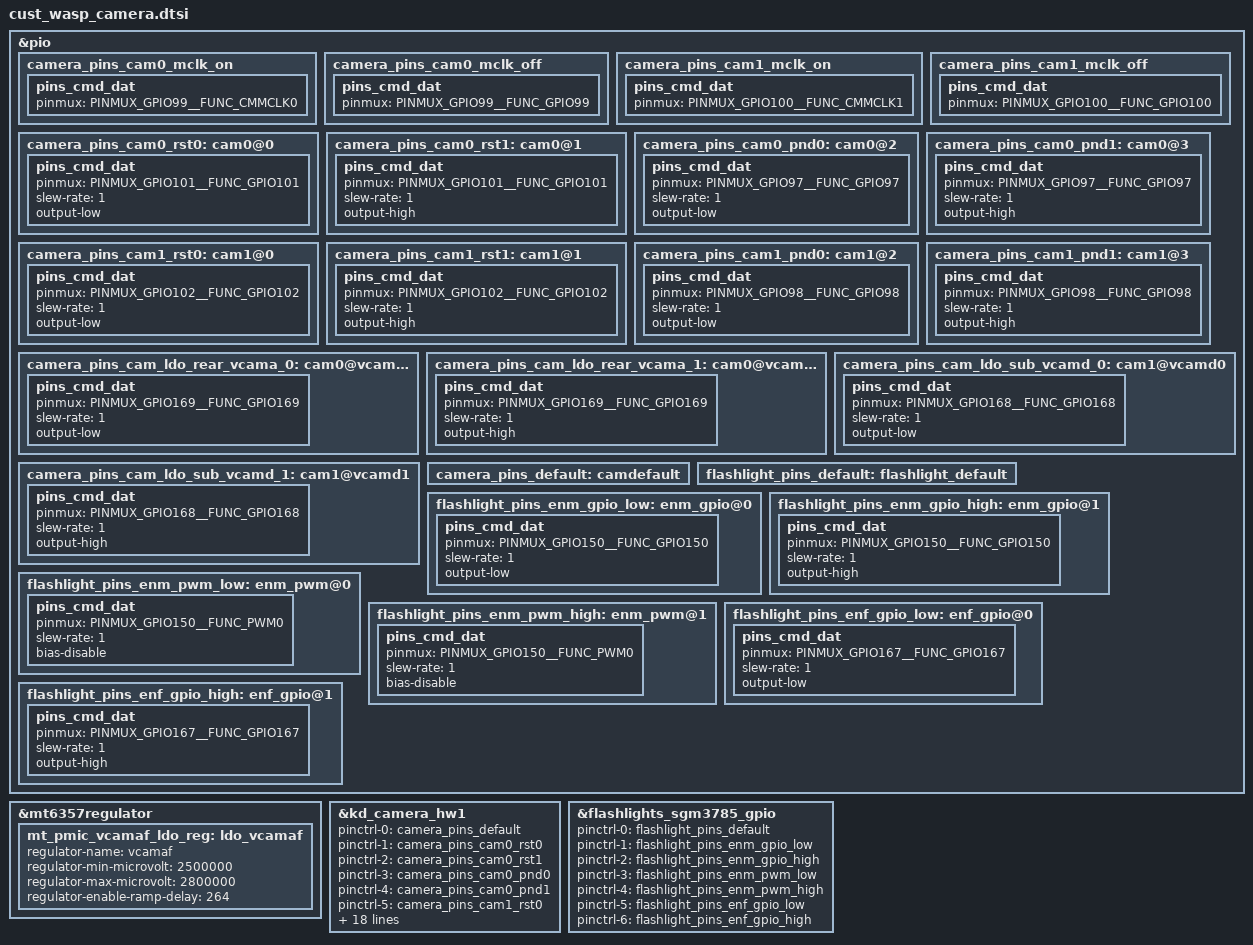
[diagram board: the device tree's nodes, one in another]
// SPDX-License-Identifier: GPL-2.0+
/*
 * Copyright (c) 2019 MediaTek Inc.
 *
 */

/* CAMERA GPIO standardization */
&pio {
	camera_pins_cam0_mclk_on: camera_pins_cam0_mclk_on {
		pins_cmd_dat {
			pinmux = <PINMUX_GPIO99__FUNC_CMMCLK0>;
		};
	};
	camera_pins_cam0_mclk_off: camera_pins_cam0_mclk_off {
		pins_cmd_dat {
			pinmux = <PINMUX_GPIO99__FUNC_GPIO99>;
		};
	};
	camera_pins_cam1_mclk_on: camera_pins_cam1_mclk_on {
		pins_cmd_dat {
			pinmux = <PINMUX_GPIO100__FUNC_CMMCLK1>;
		};
	};
	camera_pins_cam1_mclk_off: camera_pins_cam1_mclk_off {
		pins_cmd_dat {
			pinmux = <PINMUX_GPIO100__FUNC_GPIO100>;
		};
	};
	camera_pins_cam0_rst0: cam0@0 {
		pins_cmd_dat {
			pinmux = <PINMUX_GPIO101__FUNC_GPIO101>;
			slew-rate = <1>;
			output-low;
		};
	};
	camera_pins_cam0_rst1: cam0@1 {
		pins_cmd_dat {
			pinmux = <PINMUX_GPIO101__FUNC_GPIO101>;
			slew-rate = <1>;
			output-high;
		};
	};
	camera_pins_cam0_pnd0: cam0@2 {
		pins_cmd_dat {
			pinmux = <PINMUX_GPIO97__FUNC_GPIO97>;
			slew-rate = <1>;
			output-low;
		};
	};
	camera_pins_cam0_pnd1: cam0@3 {
		pins_cmd_dat {
			pinmux = <PINMUX_GPIO97__FUNC_GPIO97>;
			slew-rate = <1>;
			output-high;
		};
	};
	camera_pins_cam1_rst0: cam1@0 {
		pins_cmd_dat {
			pinmux = <PINMUX_GPIO102__FUNC_GPIO102>;
			slew-rate = <1>;
			output-low;
		};
	};
	camera_pins_cam1_rst1: cam1@1 {
		pins_cmd_dat {
			pinmux = <PINMUX_GPIO102__FUNC_GPIO102>;
			slew-rate = <1>;
			output-high;
		};
	};
	camera_pins_cam1_pnd0: cam1@2 {
		pins_cmd_dat {
			pinmux = <PINMUX_GPIO98__FUNC_GPIO98>;
			slew-rate = <1>;
			output-low;
		};
	};
	camera_pins_cam1_pnd1: cam1@3 {
		pins_cmd_dat {
			pinmux = <PINMUX_GPIO98__FUNC_GPIO98>;
			slew-rate = <1>;
			output-high;
		};
	};
	camera_pins_cam_ldo_rear_vcama_0: cam0@vcama0 {
		pins_cmd_dat {
			pinmux = <PINMUX_GPIO169__FUNC_GPIO169>;
			slew-rate = <1>;
			output-low;
		};
	};
	camera_pins_cam_ldo_rear_vcama_1: cam0@vcama1 {
		pins_cmd_dat {
			pinmux = <PINMUX_GPIO169__FUNC_GPIO169>;
			slew-rate = <1>;
			output-high;
		};
	};
	camera_pins_cam_ldo_sub_vcamd_0: cam1@vcamd0 {
		pins_cmd_dat {
			pinmux = <PINMUX_GPIO168__FUNC_GPIO168>;
			slew-rate = <1>;
			output-low;
		};
	};
	camera_pins_cam_ldo_sub_vcamd_1: cam1@vcamd1 {
		pins_cmd_dat {
			pinmux = <PINMUX_GPIO168__FUNC_GPIO168>;
			slew-rate = <1>;
			output-high;
		};
	};
	camera_pins_default: camdefault {
	};
};

&mt6357regulator {
	mt_pmic_vcamaf_ldo_reg: ldo_vcamaf {
		regulator-name = "vcamaf";
		regulator-min-microvolt = <2500000>;
		regulator-max-microvolt = <2800000>;
		regulator-enable-ramp-delay = <264>;
	};
};

&kd_camera_hw1 {
	pinctrl-names = "default",
			"cam0_rst0",
			"cam0_rst1",
			"cam0_pnd0",
			"cam0_pnd1",
			"cam1_rst0",
			"cam1_rst1",
			"cam1_pnd0",
			"cam1_pnd1",
			"cam0_vcama_on",
			"cam0_vcama_off",
			"cam1_vcamd_on",
			"cam1_vcamd_off",
			"cam0_mclk_on",
			"cam0_mclk_off",
			"cam1_mclk_on",
			"cam1_mclk_off";

	pinctrl-0 = <&camera_pins_default>;
	pinctrl-1 = <&camera_pins_cam0_rst0>;
	pinctrl-2 = <&camera_pins_cam0_rst1>;
	pinctrl-3 = <&camera_pins_cam0_pnd0>;
	pinctrl-4 = <&camera_pins_cam0_pnd1>;
	pinctrl-5 = <&camera_pins_cam1_rst0>;
	pinctrl-6 = <&camera_pins_cam1_rst1>;
	pinctrl-7 = <&camera_pins_cam1_pnd0>;
	pinctrl-8 = <&camera_pins_cam1_pnd1>;
	pinctrl-9 = <&camera_pins_cam_ldo_rear_vcama_1>;
	pinctrl-10 = <&camera_pins_cam_ldo_rear_vcama_0>;
	pinctrl-11 = <&camera_pins_cam_ldo_sub_vcamd_1>;
	pinctrl-12 = <&camera_pins_cam_ldo_sub_vcamd_0>;
	pinctrl-13 = <&camera_pins_cam0_mclk_on>;
	pinctrl-14 = <&camera_pins_cam0_mclk_off>;
	pinctrl-15 = <&camera_pins_cam1_mclk_on>;
	pinctrl-16 = <&camera_pins_cam1_mclk_off>;

	cam0_vcama-supply = <&mt_pmic_vcama_ldo_reg>;
	cam0_vcamd-supply = <&mt_pmic_vcamd_ldo_reg>;
	cam1_vcama-supply = <&mt_pmic_vcama_ldo_reg>;
	cam1_vcamd-supply = <&mt_pmic_vcamd_ldo_reg>;
	cam0_vcamio-supply = <&mt_pmic_vcamio_ldo_reg>;
	cam1_vcamio-supply = <&mt_pmic_vcamio_ldo_reg>;
	cam0_vcamaf-supply = <&mt_pmic_vcamaf_ldo_reg>;
	status = "okay";
};

&flashlights_sgm3785_gpio {
	pinctrl-names = "flashlight_default",
			"flashlight_enm_gpio_low",
			"flashlight_enm_gpio_high",
			"flashlight_enm_pwm_low", 
			"flashlight_enm_pwm_high",
			"flashlight_enf_gpio_low",
			"flashlight_enf_gpio_high";

	pinctrl-0 = <&flashlight_pins_default>;
	pinctrl-1 = <&flashlight_pins_enm_gpio_low>;
	pinctrl-2 = <&flashlight_pins_enm_gpio_high>;
	pinctrl-3 = <&flashlight_pins_enm_pwm_low>;
	pinctrl-4 = <&flashlight_pins_enm_pwm_high>;
	pinctrl-5 = <&flashlight_pins_enf_gpio_low>;
	pinctrl-6 = <&flashlight_pins_enf_gpio_high>;
	status = "okay";
};

&pio {
	flashlight_pins_default: flashlight_default {
	};

	/*torch_en*/
	flashlight_pins_enm_gpio_low: enm_gpio@0 {
		pins_cmd_dat {
			pinmux = <PINMUX_GPIO150__FUNC_GPIO150>; /* (0x9600 >> 8) | 0 */
			slew-rate = <1>; /*direction 0:in, 1:out*/
			output-low;/*direction out used only. output_low or high*/
		};
	};

	flashlight_pins_enm_gpio_high: enm_gpio@1 {
		pins_cmd_dat {
			pinmux = <PINMUX_GPIO150__FUNC_GPIO150>; /* (0x9600 >> 8) | 0 */
			slew-rate = <1>; /*direction 0:in, 1:out*/
			output-high;/*direction out used only. output_low or high*/
		};
	};
	flashlight_pins_enm_pwm_low: enm_pwm@0 {
		pins_cmd_dat {
			pinmux = <PINMUX_GPIO150__FUNC_PWM0>; /* (0x9601 >> 8) | 1 */
			slew-rate = <1>;
			bias-disable;
		};
	};
	flashlight_pins_enm_pwm_high: enm_pwm@1 {
		pins_cmd_dat {
			pinmux = <PINMUX_GPIO150__FUNC_PWM0>; /* (0x9601 >> 8) | 1 */
			slew-rate = <1>;
			bias-disable;
		};
	};

	/*flash*/
	flashlight_pins_enf_gpio_low: enf_gpio@0 {
		pins_cmd_dat {
			pinmux = <PINMUX_GPIO167__FUNC_GPIO167>; /* (0xa700 >> 8) | 0 */
			slew-rate = <1>;
			output-low;
		};
	};
	flashlight_pins_enf_gpio_high: enf_gpio@1 {
		pins_cmd_dat {
			pinmux = <PINMUX_GPIO167__FUNC_GPIO167>; /* (0xa700 >> 8) | 0 */
			slew-rate = <1>;
			output-high;
		};
	};
};

/* CAMERA GPIO end */
